# STM32C591 register map
File version: 1.0.0
CPU: CM33 r0p4, little endian, MPU, FPU, 4 interrupt priority bits
Registers are 32-bit, read-write, reset 0x0 unless marked. A register's access mark holds for its fields unless they carry their own. Offsets are from the block's base; [hi:lo] are bit positions; {n}, {i} and the like mark numbered series; 'fields as' and 'values as' point back to an identical list.

## ETH — ETH register block
Base 0x40028000
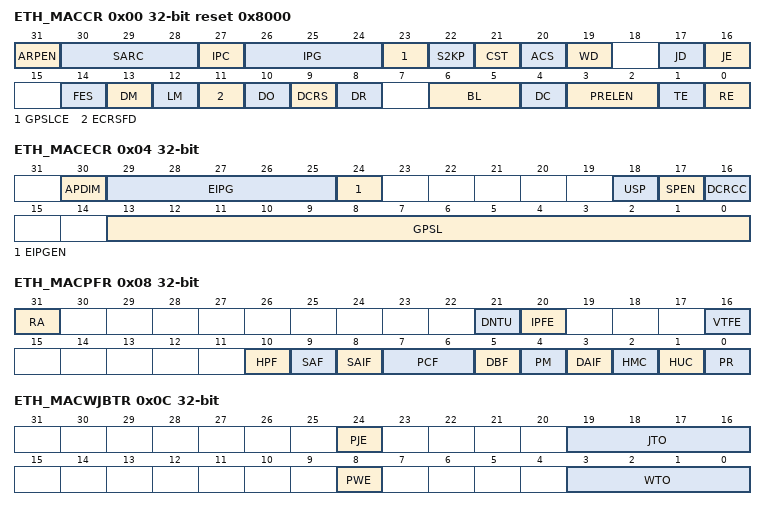
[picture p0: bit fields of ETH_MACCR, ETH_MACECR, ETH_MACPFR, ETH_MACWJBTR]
0x00 ETH_MACCR reset 0x8000 — Operating mode configuration register
  [31] ARPEN — ARP Offload Enable
  [30:28] SARC — Source Address Insertion or Replacement Control
    2=the MAC inserts the content of the MAC Address 0 registers (MAC Address 0 high register (ETH_MACA0HR) and MAC Address x low register (ETH_MACAxLR)) in the SA field of all transmitted packets; 3=the MAC replaces the content of the MAC Address 0 registers (MAC Address 0 high register (ETH_MACA0HR) and MAC Address x low register (ETH_MACAxLR)) in the SA field of all transmitted packets; 6=the MAC inserts the content of the MAC Address 1 registers (MAC Address x high register (ETH_MACAxHR) and MAC Address x low register (ETH_MACAxLR)) in the SA field of all transmitted packets; 7=the MAC replaces the content of the MAC Address 1 registers (MAC Address x high register (ETH_MACAxHR) and MAC Address x low register (ETH_MACAxLR)) in the SA field of all transmitted packets
  [27] IPC — Checksum Offload
  [26:24] IPG — Inter-Packet Gap
    0=96 bit times; 1=88 bit times; 2=80 bit times; 7=40 bit times
  [23] GPSLCE — Giant Packet Size Limit Control Enable
  [22] S2KP — IEEE 802.3as Support for 2K Packets
  [21] CST — CRC stripping for Type packets
  [20] ACS — Automatic Pad or CRC Stripping
  [19] WD — Watchdog Disable
  [17] JD — Jabber Disable
  [16] JE — Jumbo Packet Enable
  [14] FES — MAC Speed
    0=10 Mbps; 1=100 Mbps
  [13] DM — Duplex Mode
  [12] LM — Loopback Mode
  [11] ECRSFD — Enable Carrier Sense Before Transmission in Full-duplex mode
  [10] DO — Disable Receive Own
  [9] DCRS — Disable Carrier Sense During Transmission
  [8] DR — Disable Retry
  [6:5] BL — Back-Off Limit
    0=k= min (n, 10); 1=k = min (n, 8); 2=k = min (n, 4); 3=k = min (n, 1)
  [4] DC — Deferral Check
  [3:2] PRELEN — Preamble Length for Transmit packets
    0=7 bytes of preamble; 1=5 bytes of preamble; 2=3 bytes of preamble
  [1] TE — Transmitter Enable
  [0] RE — Receiver Enable
0x04 ETH_MACECR — Extended operating mode configuration register
  [30] APDIM — ARP Packet Drop if IP Address Mismatch
  [29:25] EIPG — Extended Inter-Packet Gap
  [24] EIPGEN — Extended Inter-Packet Gap Enable
  [18] USP — Unicast Slow Protocol Packet Detect
  [17] SPEN — Slow Protocol Detection Enable
  [16] DCRCC — Disable CRC Checking for Received Packets
  [13:0] GPSL — Giant Packet Size Limit
0x08 ETH_MACPFR — Packet filtering control register
  [31] RA — Receive All
  [21] DNTU — Drop Non-TCP/UDP over IP Packets
  [20] IPFE — Layer 3 and Layer 4 Filter Enable
  [16] VTFE — VLAN Tag Filter Enable
  [10] HPF — Hash or Perfect Filter
  [9] SAF — Source Address Filter Enable
  [8] SAIF — SA Inverse Filtering
  [7:6] PCF — Pass Control Packets
    0=The MAC filters all control packets from reaching the application; 1=The MAC forwards all control packets except Pause packets to the application even if they fail the Address filter; 2=The MAC forwards all control packets to the application even if they fail the Address filter; 3=The MAC forwards the control packets that pass the Address filter
  [5] DBF — Disable Broadcast Packets
  [4] PM — Pass All Multicast
  [3] DAIF — DA Inverse Filtering
  [2] HMC — Hash Multicast
  [1] HUC — Hash Unicast
  [0] PR — Promiscuous Mode
0x0C ETH_MACWJBTR — Watchdog and jabber timeout register
  [24] PJE — Programmable Jabber Enable
  [19:16] JTO — Jabber Timeout
    {v}={v+2} Kbytes (v=0..3); 12=14 Kbytes; 13=15 Kbytes; 14=16383 Bytes
  [8] PWE — Programmable Watchdog Enable
  [3:0] WTO — Watchdog Timeout
    values as JTO
0x10 ETH_MACHT0R — Hash Table 0 register
  [31:0] HT31T0 — MAC Hash Table First 32 Bits
0x14 ETH_MACHT1R — Hash Table 1 register
  [31:0] HT63T32 — MAC Hash Table Second 32 Bits
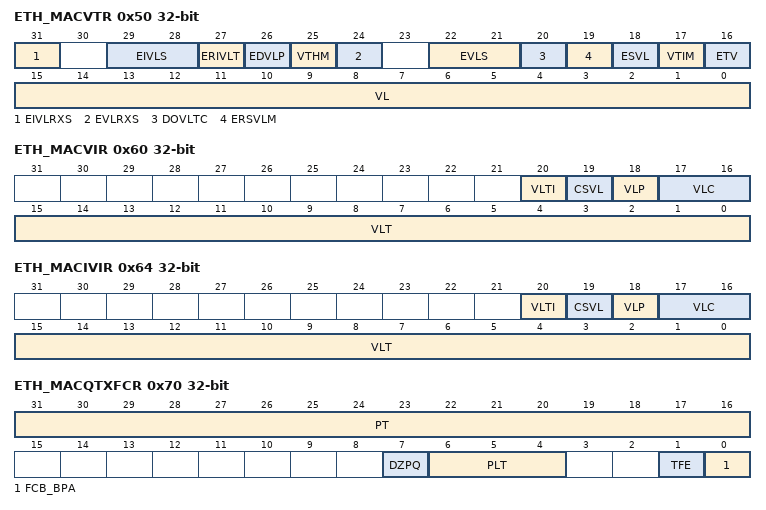
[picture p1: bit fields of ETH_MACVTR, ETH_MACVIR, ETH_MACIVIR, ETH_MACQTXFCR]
0x50 ETH_MACVTR — VLAN tag register
  [31] EIVLRXS — Enable Inner VLAN Tag in Rx Status
  [29:28] EIVLS — Enable Inner VLAN Tag Stripping on Receive
    0=Do not strip; 1=Strip if VLAN filter passes; 2=Strip if VLAN filter fails; 3=Always strip
  [27] ERIVLT — Enable Inner VLAN Tag
  [26] EDVLP — Enable Double VLAN Processing
  [25] VTHM — VLAN Tag Hash Table Match Enable
  [24] EVLRXS — Enable VLAN Tag in Rx status
  [22:21] EVLS — Enable VLAN Tag Stripping on Receive
    values as EIVLS
  [20] DOVLTC — Disable VLAN Type Check
  [19] ERSVLM — Enable Receive S-VLAN Match
  [18] ESVL — Enable S-VLAN
  [17] VTIM — VLAN Tag Inverse Match Enable
  [16] ETV — Enable 12-Bit VLAN Tag Comparison
  [15:0] VL — VLAN Tag Identifier for Receive Packets
0x58 ETH_MACVHTR — VLAN Hash table register
  [15:0] VLHT — VLAN Hash Table
0x60 ETH_MACVIR — VLAN inclusion register
  [20] VLTI — VLAN Tag Input
  [19] CSVL — C-VLAN or S-VLAN
    0=C-LAN; 1=S-LAN
  [18] VLP — VLAN Priority Control
  [17:16] VLC — VLAN Tag Control in Transmit Packets
    0=No VLAN tag deletion, insertion, or replacement; 1=VLAN tag deletion. The MAC removes the VLAN type (bytes 13 and 14) and VLAN tag (bytes 15 and 16) of all transmitted packets with VLAN tags.; 2=VLAN tag insertion. The MAC inserts VLT in bytes 15 and 16 of the packet after inserting the Type value (0x8100 or 0x88a8) in bytes 13 and 14. This operation is performed on all transmitted packets, irrespective of whether they already have a VLAN tag.; 3=VLAN tag replacement. The MAC replaces VLT in bytes 15 and 16 of all VLAN-type transmitted packets (Bytes 13 and 14 are 0x8100 or 0x88a8).
  [15:0] VLT — VLAN Tag for Transmit Packets
0x64 ETH_MACIVIR — Inner VLAN inclusion register
  [20] VLTI — VLAN Tag Input
  [19] CSVL — C-VLAN or S-VLAN
    0=C-LAN; 1=S-LAN
  [18] VLP — VLAN Priority Control
  [17:16] VLC — VLAN Tag Control in Transmit Packets
    0=No VLAN tag deletion, insertion, or replacement; 1=VLAN tag deletion; 2=VLAN tag insertion; 3=VLAN tag replacement
  [15:0] VLT — VLAN Tag for Transmit Packets
0x70 ETH_MACQTXFCR — Tx Queue flow control register
  [31:16] PT — Pause Time
  [7] DZPQ — Disable Zero-Quanta Pause
  [6:4] PLT — Pause Low Threshold
    0=Pause Time minus 4 Slot Times (PT -4 slot times); 1=Pause Time minus 28 Slot Times (PT -28 slot times); 2=Pause Time minus 36 Slot Times (PT -36 slot times); 3=Pause Time minus 144 Slot Times (PT -144 slot times); 4=Pause Time minus 256 Slot Times (PT -256 slot times); 5=Pause Time minus 512 Slot Times (PT -512 slot times)
  [1] TFE — Transmit Flow Control Enable
  [0] FCB_BPA — Flow Control Busy or Backpressure Activate
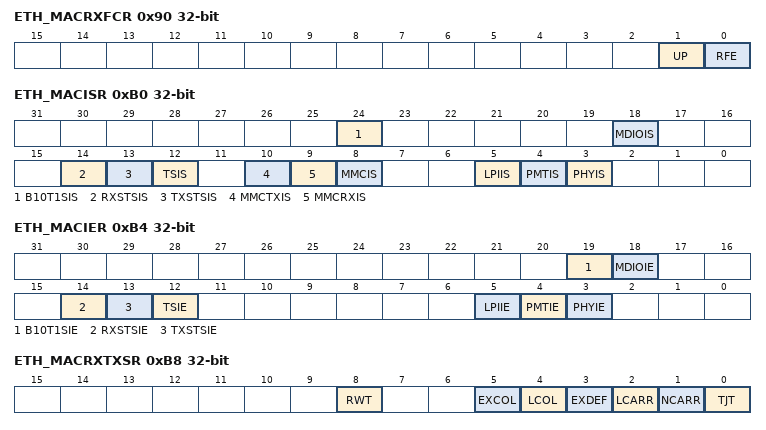
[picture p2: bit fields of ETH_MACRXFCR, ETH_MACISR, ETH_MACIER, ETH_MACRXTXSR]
0x90 ETH_MACRXFCR — Rx flow control register
  [1] UP — Unicast Pause Packet Detect
  [0] RFE — Receive Flow Control Enable
0xB0 ETH_MACISR — Interrupt status register
  [24] B10T1SIS ro — 10BT1S Interrupt Status
    0=10BT1S Interrupt status not active; 1=10BT1S Interrupt status active
  [18] MDIOIS — MDIO Interrupt Status
  [14] RXSTSIS — Receive Status Interrupt
  [13] TXSTSIS — Transmit Status Interrupt
  [12] TSIS — Timestamp Interrupt Status
  [10] MMCTXIS ro — MMC Transmit Interrupt Status
  [9] MMCRXIS ro — MMC Receive Interrupt Status
  [8] MMCIS ro — MMC Interrupt Status
  [5] LPIIS ro — LPI Interrupt Status
  [4] PMTIS ro — PMT Interrupt Status
  [3] PHYIS ro — PHY Interrupt
0xB4 ETH_MACIER — Interrupt enable register
  [19] B10T1SIE — 10BT1S Interrupt Enable
    0=10BT1S interrupt is disabled; 1=10BT1S Interrupt is enabled
  [18] MDIOIE — MDIO Interrupt Enable
  [14] RXSTSIE — Receive Status Interrupt Enable
  [13] TXSTSIE — Transmit Status Interrupt Enable
  [12] TSIE — Timestamp Interrupt Enable
  [5] LPIIE — LPI Interrupt Enable
  [4] PMTIE — PMT Interrupt Enable
  [3] PHYIE — PHY Interrupt Enable
0xB8 ETH_MACRXTXSR — Rx Tx status register
  [8] RWT — Receive Watchdog Timeout
  [5] EXCOL — Excessive Collisions
  [4] LCOL — Late Collision
  [3] EXDEF — Excessive Deferral
  [2] LCARR — Loss of Carrier
  [1] NCARR — No Carrier
  [0] TJT — Transmit Jabber Timeout
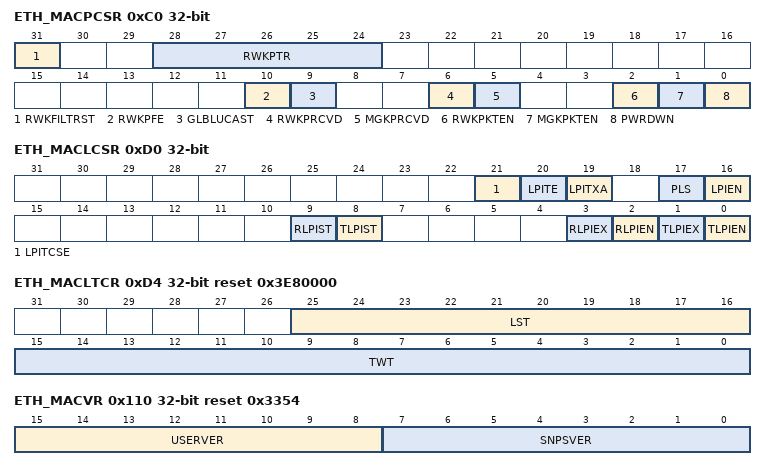
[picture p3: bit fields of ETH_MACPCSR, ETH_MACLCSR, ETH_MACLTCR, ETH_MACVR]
0xC0 ETH_MACPCSR — PMT control status register
  [31] RWKFILTRST — Remote Wake-up Packet Filter Register Pointer Reset
  [28:24] RWKPTR ro — Remote wake-up FIFO Pointer
  [10] RWKPFE — Remote wake-up Packet Forwarding Enable
  [9] GLBLUCAST — Global Unicast
  [6] RWKPRCVD ro — Remote wake-up Packet Received
  [5] MGKPRCVD — Magic Packet Received
  [2] RWKPKTEN — Remote wake-up Packet Enable
  [1] MGKPKTEN — Magic Packet Enable
  [0] PWRDWN — Power Down
0xC4 ETH_MACRWKPFR — Remote wake-up packet filter register
  [31:0] MACRWKPFR — Remote wake-up packet filter
0xD0 ETH_MACLCSR — LPI control and status register
  [21] LPITCSE — LPI Tx Clock Stop Enable
  [20] LPITE — LPI Timer Enable
  [19] LPITXA — LPI Tx Automate
  [17] PLS — PHY Link Status
  [16] LPIEN — LPI Enable
  [9] RLPIST ro — Receive LPI State
  [8] TLPIST ro — Transmit LPI State
  [3] RLPIEX ro — Receive LPI Exit
  [2] RLPIEN ro — Receive LPI Entry
  [1] TLPIEX ro — Transmit LPI Exit
  [0] TLPIEN ro — Transmit LPI Entry
0xD4 ETH_MACLTCR reset 0x3E80000 — LPI timers control register
  [25:16] LST — LPI LS Timer
  [15:0] TWT — LPI TW Timer
0xD8 ETH_MACLETR — LPI entry timer register
  [19:0] LPIET — LPI Entry Timer
0xDC ETH_MAC1USTCR reset 0x63 — One-microsecond-tick counter register
  [11:0] TIC_1US_CNTR — 1us tick Counter
0x110 ETH_MACVR ro reset 0x3354 — Version register
  [15:8] USERVER — ST-defined version
  [7:0] SNPSVER — IP version
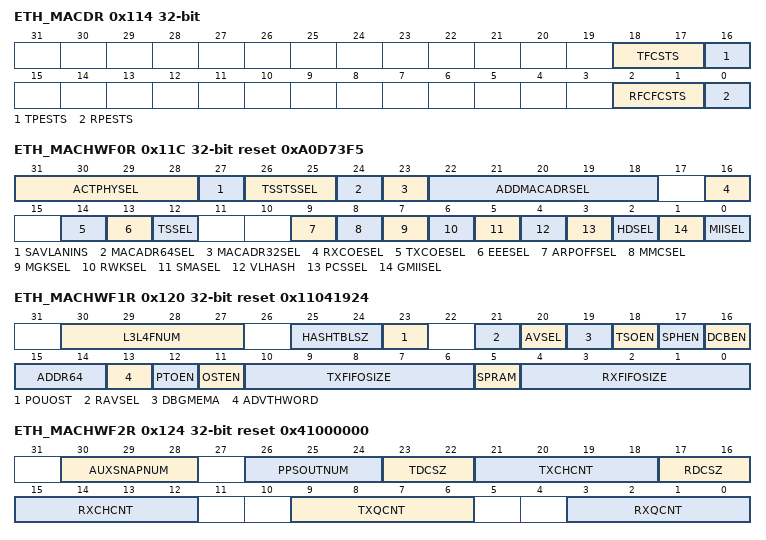
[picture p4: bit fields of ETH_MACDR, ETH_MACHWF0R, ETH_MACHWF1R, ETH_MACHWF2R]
0x114 ETH_MACDR ro — Debug register
  [18:17] TFCSTS — MAC Transmit Packet Controller Status
    0=Idle state; 1=Waiting for one of the following:; 2=Generating and transmitting a Pause control packet (in Full-duplex mode); 3=Transferring input packet for transmission
  [16] TPESTS — MAC MII Transmit Protocol Engine Status
  [2:1] RFCFCSTS — MAC Receive Packet Controller FIFO Status
  [0] RPESTS — MAC MII Receive Protocol Engine Status
0x11C ETH_MACHWF0R ro reset 0xA0D73F5 — HW feature 0 register
  [31:28] ACTPHYSEL — Active PHY selected
    0=GMII or MII; 1=RGMII; 2=SGMII; 3=TBI; 4=RMII; 5=RTBI; 6=SMII; 8=B10T1S
  [27] SAVLANINS — Source Address or VLAN Insertion Enable
  [26:25] TSSTSSEL — Timestamp System Time Source
    1=Internal; 2=External; 3=Both
  [24] MACADR64SEL — MAC Addresses 64-127 Selected
  [23] MACADR32SEL — MAC Addresses 32-63 Selected
  [22:18] ADDMACADRSEL — MAC Addresses 1-31 Selected
  [16] RXCOESEL — Receive Checksum Offload Enabled
  [14] TXCOESEL — Transmit Checksum Offload Enabled
  [13] EEESEL — Energy Efficient Ethernet Enabled
  [12] TSSEL — IEEE 1588-2008 Timestamp Enabled
  [9] ARPOFFSEL — ARP Offload Enabled
  [8] MMCSEL — RMON Module Enable
  [7] MGKSEL — PMT Magic Packet Enable
  [6] RWKSEL — PMT Remote Wake-up Packet Enable
  [5] SMASEL — SMA (MDIO) Interface
  [4] VLHASH — VLAN Hash Filter Selected
  [3] PCSSEL — PCS Registers (TBI, SGMII, or RTBI PHY interface)
  [2] HDSEL — Half-duplex Support
  [1] GMIISEL — 1000 Mbps Support
  [0] MIISEL — 10 or 100 Mbps Support
0x120 ETH_MACHWF1R ro reset 0x11041924 — HW feature 1 register
  [30:27] L3L4FNUM — Total number of L3 or L4 Filters
    0=No L3 or L4 Filter; 1=1 L3 or L4 Filter; 2=2 L3 or L4 Filters; 8=8 L3 or L4
  [25:24] HASHTBLSZ — Hash Table Size
    0=No Hash table; 1=64; 2=128; 3=256
  [23] POUOST — One Step for PTP over UDP/IP Feature Enable
  [21] RAVSEL — Rx Side Only AV Feature Enable
  [20] AVSEL — AV Feature Enable
  [19] DBGMEMA — DMA Debug Registers Enable
  [18] TSOEN — TCP Segmentation Offload Enable
  [17] SPHEN — Split Header Feature Enable
  [16] DCBEN — DCB Feature Enable
  [15:14] ADDR64 — Address width
    0=32 bits
  [13] ADVTHWORD — IEEE 1588 High Word Register Enable
  [12] PTOEN — PTP Offload Enable
  [11] OSTEN — One-Step Timestamping Enable
  [10:6] TXFIFOSIZE — MTL Transmit FIFO Size
    0=128 bytes; 1=256 bytes; 2=512 bytes; 3=1,024 bytes; 4=2,048 bytes; 5=4,096 bytes; 6=8,192 bytes; 7=16,384 bytes; 8=32 Kbytes; 9=64 Kbytes; 10=128 Kbytes
  [5] SPRAM — Single Port RAM Enable
  [4:0] RXFIFOSIZE — MTL Receive FIFO Size
    0=128 bytes; 1=256 bytes; 2=512 bytes; 3=1,024 bytes; 4=2,048 bytes; 5=4,096 bytes; 6=8,192 bytes; 7=16,384 bytes; 8=32 Kbytes; 9=64 Kbytes; 10=128 Kbytes; 11=256 Kbytes
0x124 ETH_MACHWF2R ro reset 0x41000000 — HW feature 2 register
  [30:28] AUXSNAPNUM — Number of Auxiliary Snapshot Inputs
    0=No auxiliary input; 1=1 auxiliary input; 2=2 auxiliary inputs; 3=3 auxiliary inputs; 4=4 auxiliary inputs
  [26:24] PPSOUTNUM — Number of PPS Outputs
    0=No PPS output; 1=1 PPS output; 2=2 PPS outputs; 3=3 PPS outputs; 4=4 PPS outputs
  [23:22] TDCSZ — Tx DMA Descriptor Cache Size in terms of 16-byte descriptors
    0=Cache not configured; 1=Four 16-byte descriptors; 2=Eight 16-byte descriptors; 3=Sixteen 16-byte descriptors
  [21:18] TXCHCNT — Number of DMA Transmit Channels
    0=1 DMA Tx Channel; 1=2 DMA Tx Channels; 7=8 DMA Tx
  [17:16] RDCSZ — Rx DMA Descriptor Cache Size in terms of 16-byte descriptors
    values as TDCSZ
  [15:12] RXCHCNT — Number of DMA Receive Channels
    0=1 DMA Rx Channel; 1=2 DMA Rx Channels; 7=8 DMA Rx
  [9:6] TXQCNT — Number of MTL Transmit Queues
    0=1 MTL Tx queue; 1=2 MTL Tx queues; 7=8 MTL Tx
  [3:0] RXQCNT — Number of MTL Receive Queues
    0=1 MTL Rx queue; 1=2 MTL Rx queues; 7=8 MTL Rx
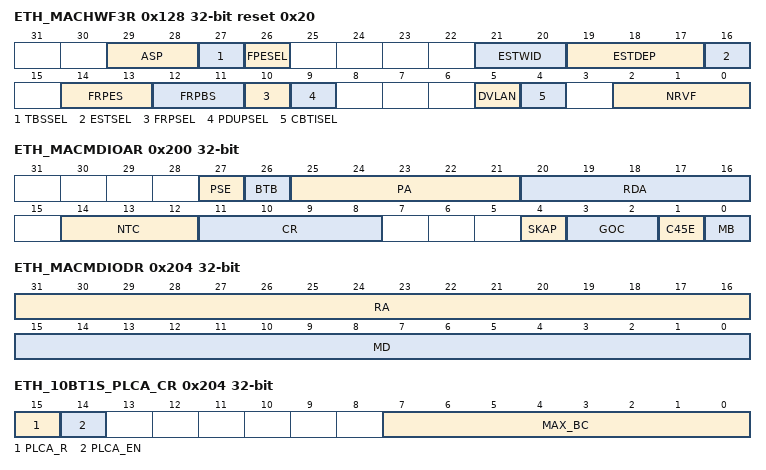
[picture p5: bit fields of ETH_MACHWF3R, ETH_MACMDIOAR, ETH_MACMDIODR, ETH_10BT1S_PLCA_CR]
0x128 ETH_MACHWF3R ro reset 0x20 — HW feature 3 register
  [29:28] ASP — Automotive Safety Package
    0=None; 1=ECC only; 2=AS_NPPE; 3=AS_PPE
  [27] TBSSEL — Time-based scheduling Enable
  [26] FPESEL — Frame Preemption Enable
  [21:20] ESTWID — Width of the Time Interval field in the Gate Control List
    0=No width; 1=16; 2=20; 3=24
  [19:17] ESTDEP — Depth of the Gate Control List
    0=No depth; 1=64; 2=128; 3=256; 4=512; 5=1024
  [16] ESTSEL — Enhancements to Scheduled Traffic Enable
  [14:13] FRPES — Flexible Receive Parser Table Entries size
    0=64 entries; 1=128 entries; 2=256 entries
  [12:11] FRPBS — Flexible Receive Parser Buffer size
    0=64 bytes; 1=128 bytes; 2=256 bytes
  [10] FRPSEL — Flexible Receive Parser Selected
  [9] PDUPSEL — Broadcast/Multicast Packet Duplication
  [5] DVLAN — Double VLAN processing enable
  [4] CBTISEL — Queue/Channel based VLAN tag insertion on Tx enable
  [2:0] NRVF — Number of Extended VLAN Tag Filters Enabled
    0=No Extended Rx VLAN Filters; 1=4 Extended Rx VLAN Filters; 2=8 Extended Rx VLAN Filters; 3=16 Extended Rx VLAN Filters; 4=24 Extended Rx VLAN Filters; 5=32 Extended Rx VLAN Filters
0x200 ETH_MACMDIOAR — MDIO address register
  [27] PSE — Preamble Suppression Enable
  [26] BTB — Back to Back transactions
  [25:21] PA — Physical Layer Address
  [20:16] RDA — Register/Device Address
  [14:12] NTC — Number of Training Clocks
  [11:8] CR — CSR Clock Range
    0=MDC clock = eth_hclk/42; 1=MDC clock = eth_hclk /62; 2=MDC clock = eth_hclk / 16; 3=MDC clock = eth_hclk / 26; 4=MDC clock = eth_hclk/102; 5=MDC clock = eth_hclk / 124; 6=MDC clock = eth_hclk/204; 7=MDC clock = eth_hclk/324; 8=eth_hclk / 4; 9=eth_hclk / 6; 10=eth_hclk / 8; 11=eth_hclk / 10; 12=eth_hclk / 12; 13=eth_hclk / 14; 14=eth_hclk / 16; 15=eth_hclk / 18
  [4] SKAP — Skip Address Packet
  [3:2] GOC — MII Operation Command
    1=Write; 2=Post Read Increment Address for Clause 45 PHY; 3=Read
  [1] C45E — Clause 45 PHY Enable
  [0] MB — MII Busy
0x204 ETH_MACMDIODR — MDIO data register
  [31:16] RA — Register Address
  [15:0] MD — MII Data
0x204 ETH_10BT1S_PLCA_CR (alternate view of ETH_MACMDIODR) — 10BT1S PLCA control register
  [15] PLCA_R — PLCA software reset
    0=Normal operation; 1=PLCA reset
  [14] PLCA_EN — PLCA functionality enable
    0=PLCA disabled; 1=PLCA enabled
  [7:0] MAX_BC — Maximum additional packets in burst mode
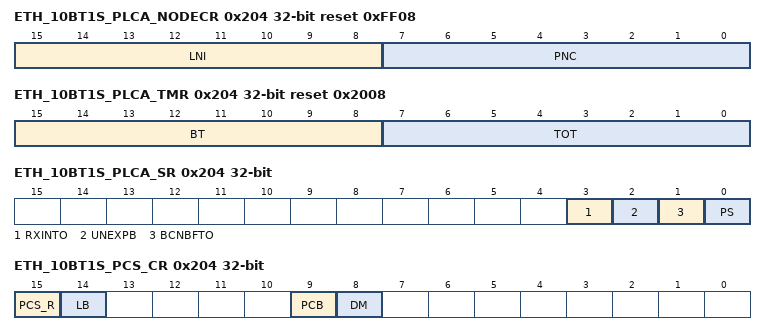
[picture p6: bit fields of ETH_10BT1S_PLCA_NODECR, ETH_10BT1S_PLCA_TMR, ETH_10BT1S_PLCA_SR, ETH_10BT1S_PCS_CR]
0x204 ETH_10BT1S_PLCA_NODECR reset 0xFF08 (alternate view of ETH_MACMDIODR) — 10BT1S PLCA node control register
  [15:8] LNI — Local_nodeID
  [7:0] PNC — PLCA node count
0x204 ETH_10BT1S_PLCA_TMR reset 0x2008 (alternate view of ETH_MACMDIODR) — 10BT1S PLCA timer register
  [15:8] BT — Burst timer
  [7:0] TOT — Transmit opportunity timer
0x204 ETH_10BT1S_PLCA_SR (alternate view of ETH_MACMDIODR) — 10BT1S PLCA status register
  [3] RXINTO — PLCA receive in assigned transmit opportunity
    0=No error; 1=RXINTO is set when the PHY asserts RXDV at the beginning of the packet in its assigned transmit opportunity. This condition indicates the existence of another node on the mixing segment on which a duplicate note ID is assigned.
  [2] UNEXPB — Unexpected BEACON
    0=No error; 1=BEACON received, which was not transmitted by a local node. Applicable to local_nodeID=0.
  [1] BCNBFTO — PCLA BEACON received before transmit opportunity
    0=No error; 1=When set, this bit indicates either multiple nodes with nodeIDs=0 on the segment, or that the node with nodeID=0 has been configured with a node count smaller than the number of nodes on the mixing segment
  [0] PS — PLCA status
    1=BEACONs are being received or transmitted, and the PLCA operates in normal mode; 0=The PLCA has been in the disable, resync, or recover state for longer than the duration of the PLCA status timer
0x204 ETH_10BT1S_PLCA_BUF_DEPTH reset 0x28 (alternate view of ETH_MACMDIODR) — 10BT1S PLCA buffer depth register
  [6:0] PVBD — PLCA Variable Buffer Depth
0x204 ETH_10BT1S_PCS_CR (alternate view of ETH_MACMDIODR) — 10BT1S PCS control register
  [15] PCS_R — PCS reset
    0=Normal operation; 1=PCS reset
  [14] LB — Loopback mode
    0=Loopback mode disabled; 1=Loopback mode enabled
  [9] PCB — PCS collision bit
    0=Collision detection through transceiver driver (ED pin); 1=Collision detection through conventional method at PCS level
  [8] DM — Duplex mode
    0=Full-duplex mode; 1=Half-duplex mode
0x204 ETH_10BT1S_PCS_SR ro (alternate view of ETH_MACMDIODR) — 10BT1S PCS status register
  [7] FAULT — This bit indicates that the 10BASE-T1S PCS has detected a fault condition either on the transmit or on the receive path.
    0=No fault condition detected; 1=Fault condition detected
0x204 ETH_10BT1S_PCS_DIAG1 ro (alternate view of ETH_MACMDIODR) — 10BT1S PCS diagnostic 1 register
  [15:0] RJC — Remote jabber counter
0x204 ETH_10BT1S_PCS_DIAG2 ro (alternate view of ETH_MACMDIODR) — 10BT1S PCS diagnostic 2 register
  [15:0] CTC — Corrupted TX count
0x204 ETH_10BT1S_PCS_JBTMR reset 0x9C40 (alternate view of ETH_MACMDIODR) — 10BT1S PCS Jabber Timer register
  [15:0] PJT — PCS unjab timer
0x204 ETH_10BT1S_PMA_EXTABLTY ro reset 0x8 (alternate view of ETH_MACMDIODR) — 10BT1S PMA extended ability register
  [3] T1SA — 10BASE-T1S ability
    1=PMA/PMD able to perform 10BASE-T1S; 0=PMA/PMD unable to perform 10BASE-T1S
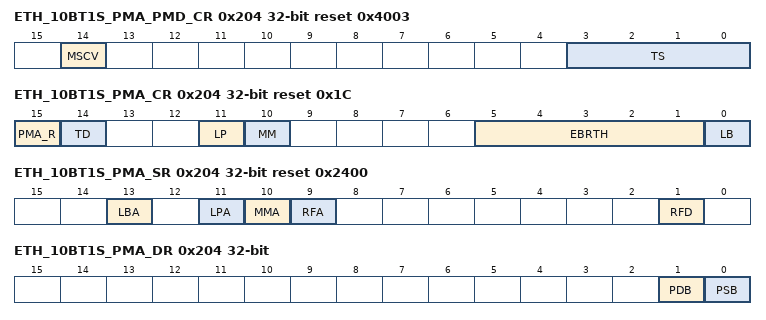
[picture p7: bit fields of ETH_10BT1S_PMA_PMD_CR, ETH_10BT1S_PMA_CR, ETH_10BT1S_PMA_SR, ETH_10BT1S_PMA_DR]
0x204 ETH_10BT1S_PMA_PMD_CR reset 0x4003 (alternate view of ETH_MACMDIODR) — 10BT1S PMA PMD control register
  [14] MSCV — Master/slave configuration value
    1=PHY configured as master; 0=PHY configured as slave
  [3:0] TS ro — Type selection
    3=10BASE-T1S
0x204 ETH_10BT1S_PMA_CR reset 0x1C (alternate view of ETH_MACMDIODR) — 10BT1S PMA control register
  [15] PMA_R — PMA reset
    1=PMA reset; 0=Normal operation
  [14] TD — Transmit disable
    1=Transmission disabled; 0=Normal operation
  [11] LP — Low power
    1=Low-power mode; 0=Normal operation
  [10] MM — Multidrop mode
    0=Operation over mixing segment network disabled; 1=Operation over mixing segment network enabled
  [5:1] EBRTH — Elastic buffer reading threshold
  [0] LB — Loopback enable
    0=Loopback mode disabled; 1=Loopback mode enabled
0x204 ETH_10BT1S_PMA_SR ro reset 0x2400 (alternate view of ETH_MACMDIODR) — 10BT1S PMA status register
  [13] LBA — Loopback ability
    1=PHY has loopback ability; 0=PHY has no loopback ability
  [11] LPA — Low-power ability
    1=PHY has low-power ability; 0=PHY has no low-power ability
  [10] MMA — Multidrop mode ability
    1=PMA has the ability to operate over a mixing segment network; 0=PMA does not have the ability to operate over a mixing segment network
  [9] RFA — Receive fault ability
    1=PMA has the ability to detect a fault condition on the receive path; 0=PMA does not have the ability to detect a fault condition on the receive path
  [1] RFD — Receive fault detection
    1=Fault condition detected; 0=No fault condition detected
0x204 ETH_10BT1S_PMA_TMCR (alternate view of ETH_MACMDIODR) — 10BT1S PMA test mode control register
  [15:13] TMC — Test mode control
    0=Normal (non-test) operation; {v}=Test mode {v} (v=1..4)
0x204 ETH_10BT1S_PMA_DR (alternate view of ETH_MACMDIODR) — 10BT1S debug mode register
  [1] PDB — PCS descrambler bypass
    0=Data descrambling is enabled; 1=Data descrambling is bypassed
  [0] PSB — PCS scrambler bypass
    0=Data scrambling is enabled; 1=Data scrambling is bypassed
0x210 ETH_MACARPAR — ARP address register
  [31:0] ARPPA — ARP Protocol Address
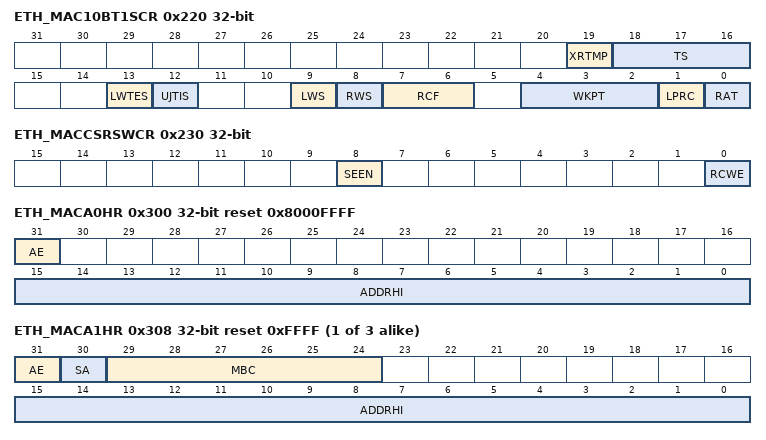
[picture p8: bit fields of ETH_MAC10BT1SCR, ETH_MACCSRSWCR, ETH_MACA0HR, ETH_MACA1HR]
0x220 ETH_MAC10BT1SCR — 10BASE-T1S control register
  [19] XRTMP — XCVR registers through MDIO pins
    0=Transceiver registers can be accessed by RX/ED pins; 1=Transceiver registers can be accessed by MDIO pins
  [18:16] TS ro — Transceiver state
    0=Normal; 1=Low-power; 2=Low-power wake-up; 3=Transmit; 4=Configuration
  [13] LWTES — 10BASE-T1S local wake-up timer expiry status
    0=XCVR is in any other states; 1=XCVR is in low-power state
  [12] UJTIS — Unjab timer interrupt status
    0=Packets transmitted with the limited packet size; 1=PCS Tx packet unjab timer done
  [9] LWS — 10BASE-T1S XCVR local wake-up status
  [8] RWS — 10BASE-T1S XCVR remote wake-up status
  [7:6] RCF — Reset command frequency
    0=1?s; 1=3?s; 2=5?s; 3=10?s
  [4:2] WKPT — Wake-up timer
    0=2s; 1=1s; 2=500ms; 3=100ms; 4=10ms; 5=1ms; 6=100?s; 7=10?s
  [1] LPRC — Low-power (sleep) request control
  [0] RAT — Register access type
    0=MDIO register space dedicated to 10BASE-T1S (PLCA/PMA/PCS) registers; 1=XCVR registers access through MDIO serial interface
0x230 ETH_MACCSRSWCR — CSR software control register
  [8] SEEN — Slave Error Response Enable
  [0] RCWE — Register Clear on Write 1 Enable
0x240 ETH_MACPRSTIMR — MAC presentation time register
  [31:0] MPTN — MAC 1722 Presentation Time in ns
0x244 ETH_MACPRSTIMUR — MAC presentation time update register
  [31:0] MPTU — MAC 1722 Presentation Time Update
0x300 ETH_MACA0HR reset 0x8000FFFF — MAC Address 0 high register
  [31] AE ro — Address Enable
  [15:0] ADDRHI — MAC Address0[47:32]
{0x304+8i} ETH_MACA{i}LR reset 0xFFFFFFFF (i=0..3) — MAC Address {i} low register
  [31:0] ADDRLO — MAC Address x [31:0]
{0x300+8i} ETH_MACA{i}HR reset 0xFFFF (i=1..3) — MAC Address {i} high register
  [31] AE — Address Enable
  [30] SA — Source Address
    0=DA; 1=SA
  [29:24] MBC — Mask Byte Control
  [15:0] ADDRHI — MAC Address1 [47:32]
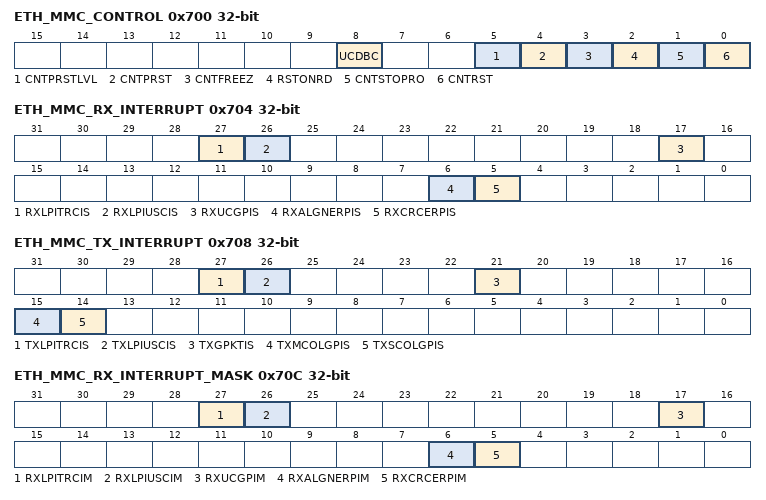
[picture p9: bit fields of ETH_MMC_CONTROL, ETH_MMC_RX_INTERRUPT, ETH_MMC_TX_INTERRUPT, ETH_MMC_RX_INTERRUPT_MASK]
0x700 ETH_MMC_CONTROL — MMC control register
  [8] UCDBC — Update MMC Counters for Dropped Broadcast Packets
  [5] CNTPRSTLVL — Full-Half Preset
  [4] CNTPRST — Counters Preset
  [3] CNTFREEZ — MMC Counter Freeze
  [2] RSTONRD — Reset on Read
  [1] CNTSTOPRO — Counter Stop Rollover
  [0] CNTRST — Counters Reset
0x704 ETH_MMC_RX_INTERRUPT — MMC Rx interrupt register
  [27] RXLPITRCIS — MMC Receive LPI transition counter interrupt status
  [26] RXLPIUSCIS — MMC Receive LPI microsecond counter interrupt status
  [17] RXUCGPIS — MMC Receive Unicast Good Packet Counter Interrupt Status
  [6] RXALGNERPIS — MMC Receive Alignment Error Packet Counter Interrupt Status
  [5] RXCRCERPIS — MMC Receive CRC Error Packet Counter Interrupt Status
0x708 ETH_MMC_TX_INTERRUPT — MMC Tx interrupt register
  [27] TXLPITRCIS — MMC Transmit LPI transition counter interrupt status
  [26] TXLPIUSCIS — MMC Transmit LPI microsecond counter interrupt status
  [21] TXGPKTIS — MMC Transmit Good Packet Counter Interrupt Status
  [15] TXMCOLGPIS — MMC Transmit Multiple Collision Good Packet Counter Interrupt Status
  [14] TXSCOLGPIS — MMC Transmit Single Collision Good Packet Counter Interrupt Status
0x70C ETH_MMC_RX_INTERRUPT_MASK — MMC Rx interrupt mask register
  [27] RXLPITRCIM — MMC Receive LPI transition counter interrupt Mask
  [26] RXLPIUSCIM — MMC Receive LPI microsecond counter interrupt Mask
  [17] RXUCGPIM — MMC Receive Unicast Good Packet Counter Interrupt Mask
  [6] RXALGNERPIM — MMC Receive Alignment Error Packet Counter Interrupt Mask
  [5] RXCRCERPIM — MMC Receive CRC Error Packet Counter Interrupt Mask
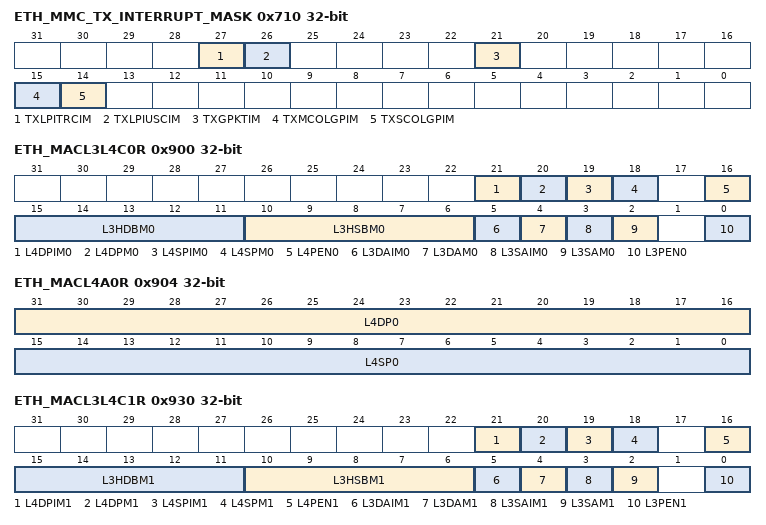
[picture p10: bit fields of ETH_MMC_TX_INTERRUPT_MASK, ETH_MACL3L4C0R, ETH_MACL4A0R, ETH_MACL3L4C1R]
0x710 ETH_MMC_TX_INTERRUPT_MASK — MMC Tx interrupt mask register
  [27] TXLPITRCIM — MMC Transmit LPI transition counter interrupt Mask
  [26] TXLPIUSCIM — MMC Transmit LPI microsecond counter interrupt Mask
  [21] TXGPKTIM — MMC Transmit Good Packet Counter Interrupt Mask
  [15] TXMCOLGPIM — MMC Transmit Multiple Collision Good Packet Counter Interrupt Mask
  [14] TXSCOLGPIM — MMC Transmit Single Collision Good Packet Counter Interrupt Mask
0x74C ETH_TX_SINGLE_COLLISION_GOOD_PACKETS ro — Tx single collision good packets register
  [31:0] TXSNGLCOLG — Tx Single Collision Good Packets
0x750 ETH_TX_MULTIPLE_COLLISION_GOOD_PACKETS ro — Tx multiple collision good packets register
  [31:0] TXMULTCOLG — Tx Multiple Collision Good Packets
0x768 ETH_TX_PACKET_COUNT_GOOD ro — Tx packet count good register
  [31:0] TXPKTG — Tx Packet Count Good
0x794 ETH_RX_CRC_ERROR_PACKETS ro — Rx CRC error packets register
  [31:0] RXCRCERR — Rx CRC Error Packets
0x798 ETH_RX_ALIGNMENT_ERROR_PACKETS ro — Rx alignment error packets register
  [31:0] RXALGNERR — Rx Alignment Error Packets
0x7C4 ETH_RX_UNICAST_PACKETS_GOOD ro — Rx unicast packets good register
  [31:0] RXUCASTG — Rx Unicast Packets Good
0x7EC ETH_TX_LPI_USEC_CNTR ro — Tx LPI microsecond timer register
  [31:0] TXLPIUSC — Tx LPI Microseconds Counter
0x7F0 ETH_TX_LPI_TRAN_CNTR ro — Tx LPI transition counter register
  [31:0] TXLPITRC — Tx LPI Transition counter
0x7F4 ETH_RX_LPI_USEC_CNTR ro — Rx LPI microsecond counter register
  [31:0] RXLPIUSC — Rx LPI Microseconds Counter
0x7F8 ETH_RX_LPI_TRAN_CNTR ro — Rx LPI transition counter register
  [31:0] RXLPITRC — Rx LPI Transition counter
0x900 ETH_MACL3L4C0R — L3 and L4 control 0 register
  [21] L4DPIM0 — Layer 4 Destination Port Inverse Match Enable
  [20] L4DPM0 — Layer 4 Destination Port Match Enable
  [19] L4SPIM0 — Layer 4 Source Port Inverse Match Enable
  [18] L4SPM0 — Layer 4 Source Port Match Enable
  [16] L4PEN0 — Layer 4 Protocol Enable
  [15:11] L3HDBM0 — Layer 3 IP DA higher bits match
    0=B_0x0_IPV4_PACKETS (No bits are masked.); 1=B_0x1_IPV4_PACKETS (LSb[0] is masked)
  [10:6] L3HSBM0 — Layer 3 IP SA higher bits match
    values as L3HDBM0
  [5] L3DAIM0 — Layer 3 IP DA Inverse Match Enable
  [4] L3DAM0 — Layer 3 IP DA Match Enable
  [3] L3SAIM0 — Layer 3 IP SA Inverse Match Enable
  [2] L3SAM0 — Layer 3 IP SA Match Enable
  [0] L3PEN0 — Layer 3 Protocol Enable
0x904 ETH_MACL4A0R — Layer4 Address filter 0 register
  [31:16] L4DP0 — Layer 4 Destination Port Number Field
  [15:0] L4SP0 — Layer 4 Source Port Number Field
0x910 ETH_MACL3A00R — Layer3 Address 0 filter 0 register
  [31:0] L3A00 — Layer 3 Address 0 Field
0x914 ETH_MACL3A10R — Layer3 Address 1 filter 0 register
  [31:0] L3A10 — Layer 3 Address 1 Field
0x918 ETH_MACL3A20R — Layer3 Address 2 filter 0 register
  [31:0] L3A20 — Layer 3 Address 2 Field
0x91C ETH_MACL3A30R — Layer3 Address 3 filter 0 register
  [31:0] L3A30 — Layer 3 Address 3 Field
0x930 ETH_MACL3L4C1R — L3 and L4 control 1 register
  [21] L4DPIM1 — Layer 4 Destination Port Inverse Match Enable
  [20] L4DPM1 — Layer 4 Destination Port Match Enable
  [19] L4SPIM1 — Layer 4 Source Port Inverse Match Enable
  [18] L4SPM1 — Layer 4 Source Port Match Enable
  [16] L4PEN1 — Layer 4 Protocol Enable
  [15:11] L3HDBM1 — Layer 3 IP DA higher bits match
    values as ETH_MACL3L4C0R.L3HDBM0
  [10:6] L3HSBM1 — Layer 3 IP SA Higher Bits Match
    values as ETH_MACL3L4C0R.L3HDBM0
  [5] L3DAIM1 — Layer 3 IP DA Inverse Match Enable
  [4] L3DAM1 — Layer 3 IP DA Match Enable
  [3] L3SAIM1 — Layer 3 IP SA Inverse Match Enable
  [2] L3SAM1 — Layer 3 IP SA Match Enable
  [0] L3PEN1 — Layer 3 Protocol Enable
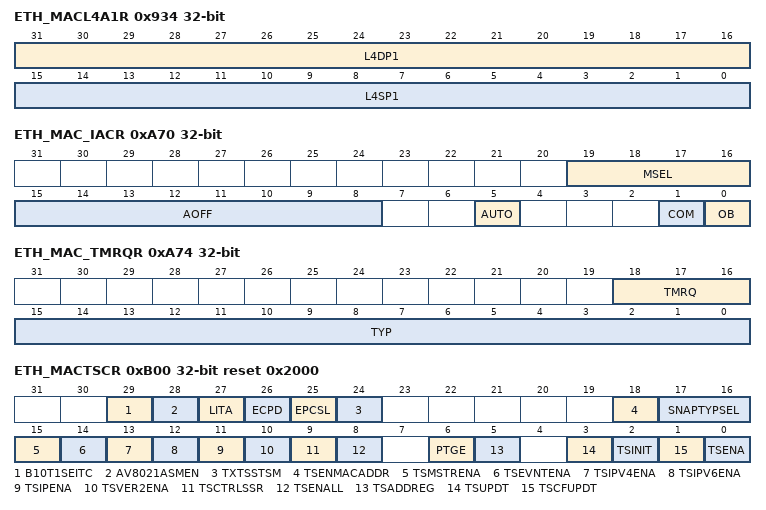
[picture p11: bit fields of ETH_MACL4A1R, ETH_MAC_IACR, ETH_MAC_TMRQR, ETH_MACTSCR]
0x934 ETH_MACL4A1R — Layer 4 address filter 1 register
  [31:16] L4DP1 — Layer 4 Destination Port Number Field
  [15:0] L4SP1 — Layer 4 Source Port Number Field
0x940 ETH_MACL3A01R — Layer3 address 0 filter 1 Register
  [31:0] L3A01 — Layer 3 Address 0 Field
0x944 ETH_MACL3A11R — Layer3 address 1 filter 1 register
  [31:0] L3A11 — Layer 3 Address 1 Field
0x948 ETH_MACL3A21R — Layer3 address 2 filter 1 Register
  [31:0] L3A21 — Layer 3 Address 2 Field
0x94C ETH_MACL3A31R — Layer3 address 3 filter 1 register
  [31:0] L3A31 — Layer 3 Address 3 Field
0xA70 ETH_MAC_IACR — MAC Indirect Access Control register
  [19:16] MSEL — Mode Select
    0=Typ_RXQ_ (Type-based RXQ mapping)
  [15:8] AOFF — Address Offset
    0=IndReg0 (Indirect register 0); 1=IndReg1 (Indirect register 1); 7=IndReg7 (Indirect register 7)
  [5] AUTO — Auto-increment
    1=AOFF is incremented by 1. The software should ensure not to cause a wrap condition. Byte-wise read/write is not supported when auto-increment is enabled.; 0=AOFF is not automatically incremented. The software should program the correct address offset for each access.
  [1] COM — Command type
    1=Indicates a read operation; 0=Indicates a write operation
  [0] OB — Operation Busy.
0xA74 ETH_MAC_TMRQR — MAC type-based Rx Queue mapping register
  [18:16] TMRQ — Type Match Rx Queue Number
  [15:0] TYP — Type field Value
0xB00 ETH_MACTSCR reset 0x2000 — Timestamp control Register
  [29] B10T1SEITC — 10BT1S External or Internal Timestamp Computation Enable
    1=The Internal Timestamp Computation is used for 10BT1S; 0=The external Timestamp Computation is used for 10BT1S
  [28] AV8021ASMEN — AV 802.1AS Mode Enable
  [27] LITA — Latency Input Based Timestamp Accuracy Disable
    1=Toggle inputs and PCS latencies are computed by MAC
  [26] ECPD — Enable Timestamp Capturing in PTP Clock Domain
  [25] EPCSL — Enable PCS latencies
    1=Timestamp captured at the egress and ingress ports includes the ingress and egress latencies provided by XPCS; 0=The XPCS latencies are not considered in the captured timestamp
  [24] TXTSSTSM — Transmit Timestamp Status Mode
  [18] TSENMACADDR — Enable MAC Address for PTP Packet Filtering
  [17:16] SNAPTYPSEL — Select PTP packets for Taking Snapshots
  [15] TSMSTRENA — Enable Snapshot for Messages Relevant to Master
  [14] TSEVNTENA — Enable Timestamp Snapshot for Event Messages
  [13] TSIPV4ENA — Enable Processing of PTP Packets Sent over IPv4-UDP
  [12] TSIPV6ENA — Enable Processing of PTP Packets Sent over IPv6-UDP
  [11] TSIPENA — Enable Processing of PTP over Ethernet Packets
  [10] TSVER2ENA — Enable PTP Packet Processing for Version 2 Format
  [9] TSCTRLSSR — Timestamp Digital or Binary Rollover Control
  [8] TSENALL — Enable Timestamp for All Packets
  [6] PTGE — Presentation Time Generation Enable
  [5] TSADDREG — Update Addend Register
  [3] TSUPDT — Update Timestamp
  [2] TSINIT — Initialize Timestamp
  [1] TSCFUPDT — Fine or Coarse Timestamp Update
  [0] TSENA — Enable Timestamp
0xB04 ETH_MACSSIR — Subsecond increment register
  [23:16] SSINC — Subsecond Increment Value
0xB08 ETH_MACSTSR ro — System time seconds register
  [31:0] TSS — Timestamp Second
0xB0C ETH_MACSTNR ro — System time nanoseconds register
  [30:0] TSSS — Timestamp subseconds
0xB10 ETH_MACSTSUR — System time seconds update register
  [31:0] TSS — Timestamp Seconds
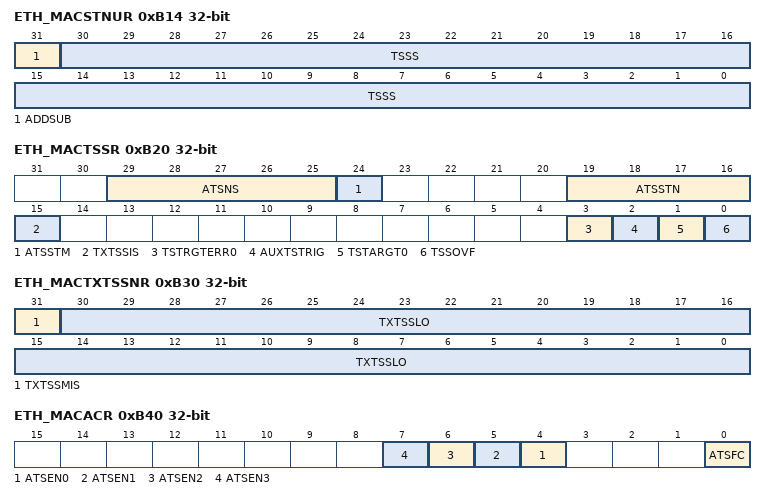
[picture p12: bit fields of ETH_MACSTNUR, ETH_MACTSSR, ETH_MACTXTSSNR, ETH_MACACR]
0xB14 ETH_MACSTNUR — System time nanoseconds update register
  [31] ADDSUB — Add or Subtract Time
  [30:0] TSSS — Timestamp subseconds
0xB18 ETH_MACTSAR — Timestamp addend register
  [31:0] TSAR — Timestamp Addend Register
0xB20 ETH_MACTSSR — Timestamp status register
  [29:25] ATSNS ro — Number of Auxiliary Timestamp Snapshots
  [24] ATSSTM — Auxiliary Timestamp Snapshot Trigger Missed
  [19:16] ATSSTN — Auxiliary Timestamp Snapshot Trigger Identifier
  [15] TXTSSIS — Tx Timestamp Status Interrupt Status
  [3] TSTRGTERR0 — Timestamp Target Time Error
  [2] AUXTSTRIG — Auxiliary Timestamp Trigger Snapshot
  [1] TSTARGT0 — Timestamp Target Time Reached
  [0] TSSOVF — Timestamp Seconds Overflow
0xB24 ETH_MACRXDTI — Rx domain time increment register
  [31:16] RXNS — Receive domain time increment value in nanoseconds
0xB28 ETH_MACTXDTI — Tx domain time increment register
  [31:16] TXNS — Transmit domain time increment value in nanoseconds
0xB30 ETH_MACTXTSSNR — Tx timestamp status nanoseconds register
  [31] TXTSSMIS ro — Transmit Timestamp Status Missed
  [30:0] TXTSSLO — Transmit Timestamp Status Low
0xB34 ETH_MACTXTSSSR ro — Tx timestamp status seconds register
  [31:0] TXTSSHI — Transmit Timestamp Status High
0xB40 ETH_MACACR — Auxiliary control register
  [n+4] ATSEN{n} (n=0..3) — Auxiliary Snapshot {n} Enable
  [0] ATSFC — Auxiliary Snapshot FIFO Clear
0xB48 ETH_MACATSNR ro — Auxiliary timestamp nanoseconds register
  [30:0] AUXTSLO — Auxiliary Timestamp
0xB4C ETH_MACATSSR ro — Auxiliary timestamp seconds register
  [31:0] AUXTSHI — Auxiliary Timestamp
0xB50 ETH_MACTSIACR — Timestamp ingress asymmetric correction register
  [31:0] OSTIAC — One-Step Timestamp Ingress Asymmetry Correction
0xB54 ETH_MACTSEACR — Timestamp egress asymmetric correction register
  [31:0] OSTEAC — One-Step Timestamp Egress Asymmetry Correction
0xB58 ETH_MACTSICNR — Timestamp Ingress correction nanosecond register
  [31:0] TSIC — Timestamp Ingress Correction
0xB5C ETH_MACTSECNR — Timestamp egress correction nanosecond register
  [31:0] TSEC — Timestamp Egress Correction
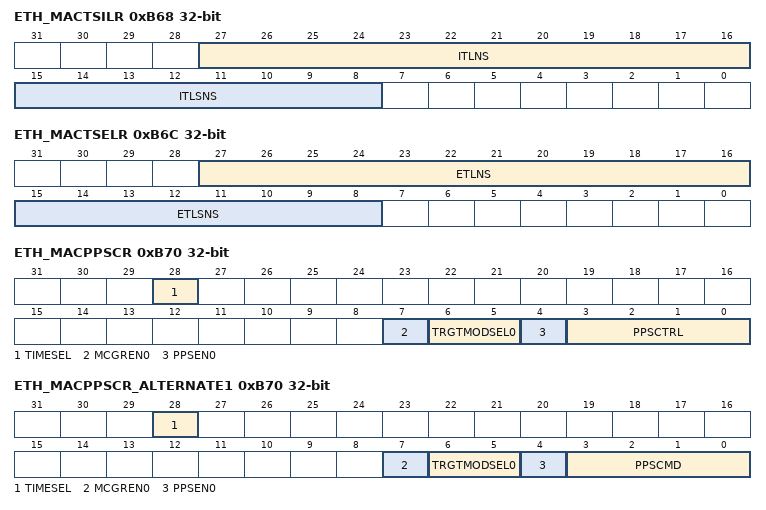
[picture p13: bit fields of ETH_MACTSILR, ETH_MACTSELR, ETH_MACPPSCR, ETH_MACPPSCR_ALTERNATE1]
0xB68 ETH_MACTSILR ro — Timestamp Ingress Latency register
  [27:16] ITLNS — Ingress Timestamp Latency, in nanoseconds
  [15:8] ITLSNS — Ingress Timestamp Latency, in subnanoseconds
0xB6C ETH_MACTSELR ro — Timestamp Egress Latency register
  [27:16] ETLNS — Egress Timestamp Latency, in nanoseconds
  [15:8] ETLSNS — Egress Timestamp Latency, in subnanoseconds
0xB70 ETH_MACPPSCR — PPS control register
  [28] TIMESEL — Time Select
  [7] MCGREN0 — MCGR Mode Enable for PPS0 Output
    0=PPS mode; 1=MCGR mode
  [6:5] TRGTMODSEL0 — Target Time Register Mode for PPS Output
    0=Target Time registers are programmed only for generating the interrupt event; 1=Enables MCGR Interrupt whose status bit is indicated by TSTARGT0 bit in Timestamp status register (ETH_MACTSSR) register; 2=Target Time registers are programmed for generating the interrupt event and starting or stopping the PPS output signal generation; 3=Target Time registers are programmed only for starting or stopping the PPS output signal generation. No interrupt is asserted.
  [4] PPSEN0 — Flexible PPS Output Mode Enable
  [3:0] PPSCTRL — PPS Output Frequency Control
    1=The binary rollover is 2 Hz, and the digital rollover is 1 Hz; 2=The binary rollover is 4 Hz, and the digital rollover is 2 Hz; 3=The binary rollover is 8 Hz, and the digital rollover is 4 Hz; 4=The binary rollover is 16 Hz, and the digital rollover is 8 Hz; 15=The binary rollover is 32.768 KHz and the digital rollover is 16.384KHz
0xB70 ETH_MACPPSCR_ALTERNATE1 (alternate view of ETH_MACPPSCR) — PPS control register
  [28] TIMESEL — Time Select
  [7] MCGREN0 — MCGR Mode Enable for PPS Output
    0=PPS mode; 1=MCGR mode
  [6:5] TRGTMODSEL0 — Target Time Register Mode for PPS Output
    values as ETH_MACPPSCR.TRGTMODSEL0
  [4] PPSEN0 — Flexible PPS Output Mode Enable
  [3:0] PPSCMD — Flexible PPS Output (eth_ptp_pps_out) Control
    0=No Command; 1=START Single Pulse; 2=START Pulse Train; 3=Cancel START; 4=STOP Pulse Train at time; 5=STOP Pulse Train immediately; 6=Cancel STOP Pulse train
0xB80 ETH_MACPPSTTSR — PPS target time seconds register
  [31:0] TSTRH0 — PPS Target Time Seconds Register
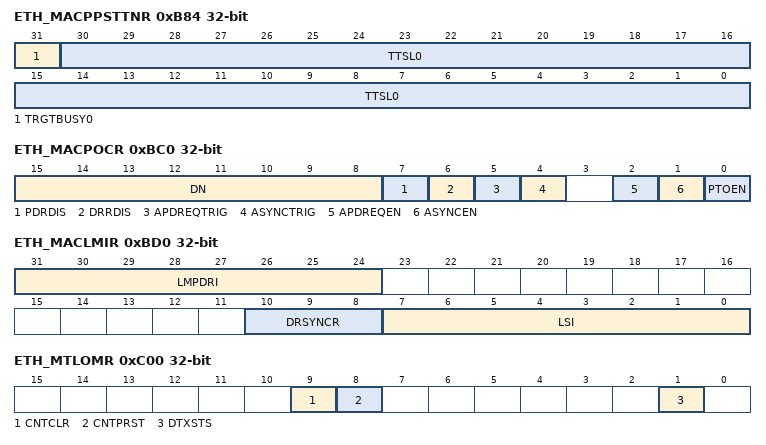
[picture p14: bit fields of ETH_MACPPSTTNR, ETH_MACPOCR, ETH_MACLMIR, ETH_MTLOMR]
0xB84 ETH_MACPPSTTNR — PPS target time nanoseconds register
  [31] TRGTBUSY0 — PPS Target Time Register Busy
  [30:0] TTSL0 — Target Time Low for PPS Register
0xB88 ETH_MACPPSIR — PPS interval register
  [31:0] PPSINT0 — PPS Output Signal Interval
0xB8C ETH_MACPPSWR — PPS width register
  [31:0] PPSWIDTH0 — PPS Output Signal Width
0xBC0 ETH_MACPOCR — PTP Offload control register
  [15:8] DN — Domain Number
  [7] PDRDIS — Disable Peer Delay Response response generation
  [6] DRRDIS — Disable PTO Delay Request/Response response generation
  [5] APDREQTRIG — Automatic PTP Pdelay_Req message Trigger
  [4] ASYNCTRIG — Automatic PTP SYNC message Trigger
  [2] APDREQEN — Automatic PTP Pdelay_Req message Enable
  [1] ASYNCEN — Automatic PTP SYNC message Enable
  [0] PTOEN — PTP Offload Enable
0xBC4 ETH_MACSPI0R — PTP Source Port Identity 0 Register
  [31:0] SPI0 — Source Port Identity 0
0xBC8 ETH_MACSPI1R — PTP Source port identity 1 register
  [31:0] SPI1 — Source Port Identity 1
0xBCC ETH_MACSPI2R — PTP Source port identity 2 register
  [15:0] SPI2 — Source Port Identity 2
0xBD0 ETH_MACLMIR — Log message interval register
  [31:24] LMPDRI — Log Min Pdelay_Req Interval
  [10:8] DRSYNCR — Delay_Req to SYNC Ratio
    0=DelayReq generated for every received SYNC; 1=DelayReq generated every alternate reception of SYNC
  [7:0] LSI — Log Sync Interval
0xC00 ETH_MTLOMR — Operating mode register
  [9] CNTCLR — Counters Reset
  [8] CNTPRST — Counters Preset
  [1] DTXSTS — Drop Transmit Status
0xC20 ETH_MTLISR ro — Interrupt status register
  [0] Q0IS — Queue interrupt status
0xD00 ETH_MTLTXQOMR reset 0x70008 — Tx queue operating mode register
  [18:16] TQS — Transmit queue size
  [6:4] TTC — Transmit Threshold Control
    0=32; 1=64; 2=96; 3=128; 4=192; 5=256; 6=384; 7=512
  [3:2] TXQEN ro — Transmit Queue Enable
    0=Not enabled; 2=Enabled
  [1] TSF — Transmit Store and Forward
  [0] FTQ — Flush Transmit Queue
0xD04 ETH_MTLTXQUR — Tx queue underflow register
  [11] UFCNTOVF — Overflow Bit for Underflow Packet Counter
  [10:0] UFFRMCNT — Underflow Packet Counter
0xD08 ETH_MTLTXQDR ro — Tx queue debug register
  [22:20] STXSTSF — Number of Status Words in Tx Status FIFO of Queue
  [18:16] PTXQ — Number of Packets in the Transmit Queue
  [5] TXSTSFSTS — MTL Tx Status FIFO Full Status
  [4] TXQSTS — MTL Tx Queue Not Empty Status
  [3] TWCSTS — MTL Tx Queue Write Controller Status
  [2:1] TRCSTS — MTL Tx Queue Read Controller Status
    0=Idle state; 1=Read state (transferring data to the MAC transmitter); 2=Waiting for pending Tx Status from the MAC transmitter; 3=Flushing the Tx queue because of the Packet Abort request from the MAC
  [0] TXQPAUSED — Transmit Queue in Pause
0xD2C ETH_MTLQICSR — Queue interrupt control status register
  [24] RXOIE — Receive Queue Overflow Interrupt Enable
  [16] RXOVFIS — Receive Queue Overflow Interrupt Status
  [8] TXUIE — Transmit Queue Underflow Interrupt Enable
  [0] TXUNFIS — Transmit Queue Underflow Interrupt Status
0xD30 ETH_MTLRXQOMR reset 0x700000 — Rx queue operating mode register
  [22:20] RQS ro — Receive Queue Size
  [6] DIS_TCP_EF — Disable Dropping of TCP/IP Checksum Error Packets
  [5] RSF — Receive Queue Store and Forward
  [4] FEP — Forward Error Packets
  [3] FUP — Forward Undersized Good Packets
  [1:0] RTC — Receive Queue Threshold Control
    0=64; 1=32; 2=96; 3=128
0xD34 ETH_MTLRXQMPOCR — Rx queue missed packet and overflow counter register
  [27] MISCNTOVF — Missed Packet Counter Overflow Bit
  [26:16] MISPKTCNT — Missed Packet Counter
  [11] OVFCNTOVF — Overflow Counter Overflow Bit
  [10:0] OVFPKTCNT — Overflow Packet Counter
0xD38 ETH_MTLRXQDR ro — Rx queue debug register
  [29:16] PRXQ — Number of Packets in Receive Queue
  [5:4] RXQSTS — MTL Rx Queue Fill-Level Status
    0=Rx queue empty; 1=Rx queue fill-level below flow-control deactivate threshold; 2=Rx queue fill-level above flow-control activate threshold; 3=Rx queue full
  [2:1] RRCSTS — MTL Rx Queue Read Controller State
    0=Idle state; 1=Reading packet data; 2=Reading packet status (or timestamp); 3=Flushing the packet data and status
  [0] RWCSTS — MTL Rx Queue Write Controller Active Status
0x1000 ETH_DMAMR — DMA mode register
  [17:16] INTM — Interrupt Mode
  [14:12] PR — Priority ratio
    {v}=The priority ratio is {v+1}:1 (v=0..7)
  [11] TXPR — Transmit priority
  [1] DA — DMA Tx or Rx Arbitration Scheme
    0=Weighted Round-Robin with Rx:Tx or Tx:Rx; 1=Fixed priority
  [0] SWR — Software Reset
0x1004 ETH_DMASBMR — System bus mode register
  [15] RB ro — Rebuild INCRx Burst
  [14] MB ro — Mixed Burst
  [12] AAL — Address-Aligned Beats
  [0] FB — Fixed Burst Length
0x1008 ETH_DMAISR ro — Interrupt status register
  [17] MACIS — MAC Interrupt Status
  [16] MTLIS — MTL Interrupt Status
  [0] DC0IS — DMA Channel Interrupt Status
0x100C ETH_DMADSR ro — Debug status register
  [15:12] TPS0 — DMA Channel Transmit Process State
    0=Stopped (Reset or Stop Transmit Command issued); 1=Running (Fetching Tx Transfer Descriptor); 2=Running (Waiting for status); 3=Running (Reading Data from system memory buffer and queuing it to the Tx buffer (Tx FIFO)); 4=Timestamp write state; 6=Suspended (Tx Descriptor Unavailable or Tx Buffer Underflow); 7=Running (Closing Tx Descriptor)
  [11:8] RPS0 — DMA Channel Receive Process State
    0=Stopped (Reset or Stop Receive Command issued); 1=Running (Fetching Rx Transfer Descriptor); 3=Running (Waiting for Rx packet); 4=Suspended (Rx Descriptor Unavailable); 5=Running (Closing the Rx Descriptor); 6=Timestamp write state; 7=Running (Transferring the received packet data from the Rx buffer to the system memory)
  [0] AXWHSTS — AHB Master Write Channel
0x1100 ETH_DMACCR — Channel control register
  [26] DRO — Descriptor refetch when OWN bit is 0
  [20:18] DSL — Descriptor Skip Length
  [16] PBLX8 — 8xPBL mode
  [13:0] MSS — Maximum Segment Size
0x1104 ETH_DMACTXCR — Channel transmit control register
  [21:16] TXPBL — Transmit Programmable Burst Length
  [12] TSE — TCP Segmentation Enabled
  [4] OSF — Operate on Second Packet
  [0] ST — Start or Stop Transmission Command
0x1108 ETH_DMACRXCR — Channel receive control register
  [31] RPF — DMA Rx Channel Packet Flush
  [21:16] RXPBL — Receive Programmable Burst Length
  [14:1] RBSZ — Receive Buffer size
  [0] SR — Start or Stop Receive
0x1114 ETH_DMACTXDLAR — Channel Tx descriptor list address register
  [31:0] TDESLA — Start of Transmit List
0x111C ETH_DMACRXDLAR — Channel Rx descriptor list address register
  [31:0] RDESLA — Start of Receive List
0x1120 ETH_DMACTXDTPR — Channel Tx descriptor tail pointer register
  [31:0] TDT — Transmit Descriptor Tail Pointer
0x1128 ETH_DMACRXDTPR — Channel Rx descriptor tail pointer register
  [31:0] RDT — Receive Descriptor Tail Pointer
0x112C ETH_DMACTXRLR — Channel Tx descriptor ring length register
  [9:0] TDRL — Transmit Descriptor Ring Length
0x1130 ETH_DMACRXRLR — Channel Rx descriptor ring length register
  [23:16] ARBS — Alternate Receive Buffer Size
  [9:0] RDRL — Receive Descriptor Ring Length
0x1134 ETH_DMACIER — Channel interrupt enable register
  [15] NIE — Normal Interrupt Summary Enable
  [14] AIE — Abnormal Interrupt Summary Enable
  [13] CDEE — Context Descriptor Error Enable
  [12] FBEE — Fatal Bus Error Enable
  [11] ERIE — Early receive interrupt Enable
  [10] ETIE — Early Transmit Interrupt Enable
  [9] RWTE — Receive Watchdog Timeout Enable
  [8] RSE — Receive Stopped Enable
  [7] RBUE — Receive Buffer Unavailable Enable
  [6] RIE — Receive Interrupt Enable
  [2] TBUE — Transmit Buffer Unavailable Enable
  [1] TXSE — Transmit Stopped Enable
  [0] TIE — Transmit Interrupt Enable
0x1138 ETH_DMACRXIWTR — Channel Rx interrupt watchdog timer register
  [31] PSEL — Packet Count Interrupt Select
    1=RBCT[9:0] is used to generate interrupt based on the number of packets received; 0=RBCT[9:0] is used to generate interrupt based on the number of bytes received
  [29:20] RBCT — Receive Byte Count Threshold
  [19:18] ITCU — Rx Idle Timer Count Units
    0=256; 1=512; 2=1024
  [17:16] RWTU — Receive Interrupt Watchdog Timer Count Units
    0=256; 1=512; 2=1024; 3=2048
  [12:8] ITW — Rx Idle Timer Window
  [7:0] RWT — Receive Interrupt Watchdog Timer Count
0x1144 ETH_DMACCATXDR ro — Channel current application transmit descriptor register
  [31:0] CURTDESAPTR — Application Transmit Descriptor Address Pointer
0x114C ETH_DMACCARXDR ro — Channel current application receive descriptor register
  [31:0] CURRDESAPTR — Application Receive Descriptor Address Pointer
0x1154 ETH_DMACCATXBR ro — Channel current application transmit buffer register
  [31:0] CURTBUFAPTR — Application Transmit Buffer Address Pointer
0x115C ETH_DMACCARXBR ro — Channel current application receive buffer register
  [31:0] CURRBUFAPTR — Application Receive Buffer Address Pointer
0x1160 ETH_DMACSR — Channel status register
  [21:19] REB ro — Rx DMA Error Bits
  [18:16] TEB ro — Tx DMA Error Bits
  [15] NIS — Normal Interrupt Summary
  [14] AIS — Abnormal Interrupt Summary
  [13] CDE — Context Descriptor Error
  [12] FBE — Fatal Bus Error
  [11] ERI — Early Receive Interrupt
  [10] ETI — Early Transmit Interrupt
  [9] RWT — Receive Watchdog Timeout
  [8] RPS — Receive Process Stopped
  [7] RBU — Receive Buffer Unavailable
  [6] RI — Receive Interrupt
  [2] TBU — Transmit Buffer Unavailable
  [1] TPS — Transmit Process Stopped
  [0] TI — Transmit Interrupt
0x1164 ETH_DMACMFCR — Channel missed frame count register
  [15] MFCO — Overflow status of the MFC Counter
  [10:0] MFC — Dropped Packet Counters
